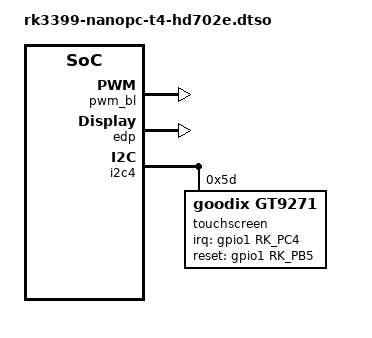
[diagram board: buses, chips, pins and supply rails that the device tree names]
// SPDX-License-Identifier: (GPL-2.0+ OR MIT)
/*
 * FriendlyElec HD702E LCD on NanoPC-T4 board
 */

/dts-v1/;
/plugin/;

#include <dt-bindings/gpio/gpio.h>
#include <dt-bindings/interrupt-controller/irq.h>
#include <dt-bindings/pinctrl/rockchip.h>

&{/} {
	pwm_bl: backlight {
		compatible = "pwm-backlight";
		pwms = <&pwm0 0 25000 0>;
		enable-gpios = <&gpio4 RK_PD5 GPIO_ACTIVE_HIGH>;
		brightness-levels = <0 255>;
		default-brightness-level = <200>;
		num-interpolated-steps = <255>;
	};
};

&edp {
	force-hpd;
	status = "okay";

	aux-bus {
		edp-panel {
			compatible = "friendlyarm,hd702e";
			backlight = <&pwm_bl>;
			no-hpd;
			power-supply = <&vcc12v0_sys>;

			port {
				panel_in_edp: endpoint {
					remote-endpoint = <&edp_out_panel>;
				};
			};
		};
	};
};

&edp_out {
	edp_out_panel: endpoint {
		remote-endpoint = <&panel_in_edp>;
	};
};

&i2c4 {
	#address-cells = <1>;
	#size-cells = <0>;

	touchscreen@5d {
		compatible = "goodix,gt9271";
		reg = <0x5d>;
		interrupt-parent = <&gpio1>;
		interrupts = <RK_PC4 IRQ_TYPE_EDGE_FALLING>;
		irq-gpios = <&gpio1 RK_PC4 GPIO_ACTIVE_HIGH>;
		reset-gpios = <&gpio1 RK_PB5 GPIO_ACTIVE_HIGH>;
	};
};
